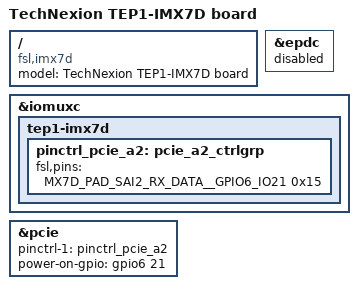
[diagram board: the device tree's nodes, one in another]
/*
 * Copyright 2016 Technexion Ltd.
 *
 * Author: Alvin Chen<alvin.chen@technexion.com>
 *
 * This program is free software; you can redistribute it and/or modify
 * it under the terms of the GNU General Public License version 2 as
 * published by the Free Software Foundation.
 *
 */
/dts-v1/;

#include <dt-bindings/interrupt-controller/irq.h>
#include "imx7d.dtsi"
#include "imx7d-tep1-a2.dtsi"
/ {
	model = "TechNexion TEP1-IMX7D board";
	compatible = "fsl,imx7d";
};

&epdc {
	status = "disabled";
};

&iomuxc {
	tep1-imx7d {
		pinctrl_pcie_a2: pcie_a2_ctrlgrp {
			fsl,pins = <
				MX7D_PAD_SAI2_RX_DATA__GPIO6_IO21       0x15    /* pcie POWER_ON_OFF */
			>;
		};
	};
};

&pcie {
	pinctrl-names = "default";
	pinctrl-1 = <&pinctrl_pcie_a2>;
	power-on-gpio = <&gpio6 21 GPIO_ACTIVE_HIGH>;
	status = "okay";
};
